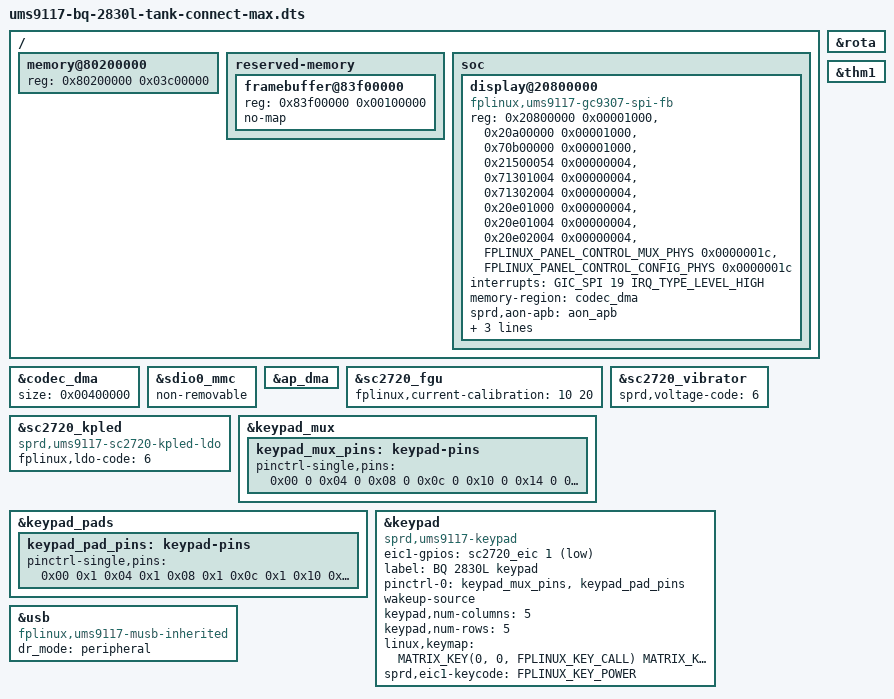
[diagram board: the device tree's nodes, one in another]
// SPDX-License-Identifier: GPL-2.0-only
/dts-v1/;

#include <dt-bindings/gpio/gpio.h>
#include <dt-bindings/input/input.h>
#include <dt-bindings/input/fplinux-keypad.h>
#include <dt-bindings/leds/common.h>
#include "ums9117.dtsi"
#include "ums9117-sc2720.dtsi"
#include "fplinux-bq-2830l-tank-connect-max-identity.dtsi"
#include "ums9117-nand-readonly.dtsi"

#include "fplinux-bq-2830l-tank-connect-max-audio-policy.dtsi"

#include "fplinux-bq-2830l-tank-connect-max-panel-addresses.h"

/ {
	memory@80200000 {
		device_type = "memory";
		reg = <0x80200000 0x03c00000>;
	};

	reserved-memory {
		ranges;
		#address-cells = <1>;
		#size-cells = <1>;

		framebuffer@83f00000 {
			reg = <0x83f00000 0x00100000>;
			no-map;
		};
	};

	soc {
		display@20800000 {
			compatible = "fplinux,ums9117-gc9307-spi-fb";
			reg = <0x20800000 0x00001000>,
			      <0x20a00000 0x00001000>,
			      <0x70b00000 0x00001000>,
			      <0x21500054 0x00000004>,
			      <0x71301004 0x00000004>,
			      <0x71302004 0x00000004>,
			      <0x20e01000 0x00000004>,
			      <0x20e01004 0x00000004>,
			      <0x20e02004 0x00000004>,
			      <FPLINUX_PANEL_CONTROL_MUX_PHYS 0x0000001c>,
			      <FPLINUX_PANEL_CONTROL_CONFIG_PHYS 0x0000001c>;
			interrupt-names = "lcdc-done";
			interrupts = <GIC_SPI 19 IRQ_TYPE_LEVEL_HIGH>;
			memory-region = <&codec_dma>;
			reg-names = "lcdc", "lcm", "spi", "spi-clock-selector",
				    "spi-reset-set", "spi-reset-clear", "ap-ahb-gate-set",
				    "ap-ahb-reset-set", "ap-ahb-reset-clear", "pinmux",
				    "pinconf";
			sprd,aon-apb = <&aon_apb>;
#include "fplinux-bq-2830l-tank-connect-max-panel.dtsi"
			sprd,pmic = <&sc2720_pmic>;
			sprd,wled-current-levels = <50 50 50 50>;
			sprd,wled-default-level = <35>;
		};
	};
};

#include "ums9117-ram-session.dtsi"
#include "radio.dtsi"
#include "camera.dtsi"
#include "audio.dtsi"

&codec_dma {
	size = <0x00400000>;
};

&sdio0_mmc {
	non-removable;

	status = "okay";
};

&ap_dma {
	status = "okay";
};

&rota {
	status = "okay";
};

&sc2720_fgu {
	fplinux,current-calibration = <10 20>;

	status = "okay";
};

&sc2720_vibrator {
	sprd,voltage-code = <6>;

	status = "okay";
};

&thm1 {
	status = "okay";
};

&sc2720_kpled {
	compatible = "sprd,ums9117-sc2720-kpled-ldo";
	fplinux,ldo-code = <6>;

	status = "okay";
};

&keypad_mux {
	keypad_mux_pins: keypad-pins {
		pinctrl-single,pins = <
			0x00 0 0x04 0 0x08 0 0x0c 0 0x10 0
			0x14 0 0x18 0 0x1c 0 0x20 0 0x24 0
		>;
	};
};

&keypad_pads {
	keypad_pad_pins: keypad-pins {
		pinctrl-single,pins = <
			0x00 0x1 0x04 0x1 0x08 0x1 0x0c 0x1 0x10 0x1
			0x14 0x8a 0x18 0x8a 0x1c 0x8a 0x20 0x8a 0x24 0x8a
		>;
	};
};

&keypad {
	compatible = "sprd,ums9117-keypad";
	eic1-gpios = <&sc2720_eic 1 GPIO_ACTIVE_LOW>;
	label = "BQ 2830L keypad";
	pinctrl-0 = <&keypad_mux_pins &keypad_pad_pins>;
	pinctrl-names = "matrix";
	wakeup-source;
	keypad,num-columns = <5>;
	keypad,num-rows = <5>;
	linux,keymap = <
		MATRIX_KEY(0, 0, FPLINUX_KEY_CALL)
		MATRIX_KEY(0, 1, FPLINUX_KEY_DOWN)
		MATRIX_KEY(0, 3, FPLINUX_KEY_RIGHT)
		MATRIX_KEY(0, 4, FPLINUX_KEY_LEFT)
		MATRIX_KEY(1, 0, FPLINUX_KEY_1)
		MATRIX_KEY(1, 1, FPLINUX_KEY_2)
		MATRIX_KEY(1, 2, FPLINUX_KEY_3)
		MATRIX_KEY(1, 3, FPLINUX_KEY_UP)
		MATRIX_KEY(1, 4, KEY_CAMERA)
		MATRIX_KEY(2, 0, FPLINUX_KEY_4)
		MATRIX_KEY(2, 1, FPLINUX_KEY_5)
		MATRIX_KEY(2, 2, FPLINUX_KEY_6)
		MATRIX_KEY(2, 3, FPLINUX_KEY_OK)
		MATRIX_KEY(3, 0, FPLINUX_KEY_7)
		MATRIX_KEY(3, 1, FPLINUX_KEY_8)
		MATRIX_KEY(3, 2, FPLINUX_KEY_9)
		MATRIX_KEY(3, 3, FPLINUX_KEY_SOFT_LEFT)
		MATRIX_KEY(4, 0, FPLINUX_KEY_STAR)
		MATRIX_KEY(4, 1, FPLINUX_KEY_0)
		MATRIX_KEY(4, 2, FPLINUX_KEY_POUND)
		MATRIX_KEY(4, 4, FPLINUX_KEY_SOFT_RIGHT)
	>;
	sprd,eic1-keycode = <FPLINUX_KEY_POWER>;

	status = "okay";
};

&usb {
	compatible = "fplinux,ums9117-musb-inherited";
	dr_mode = "peripheral";

	status = "okay";
};
